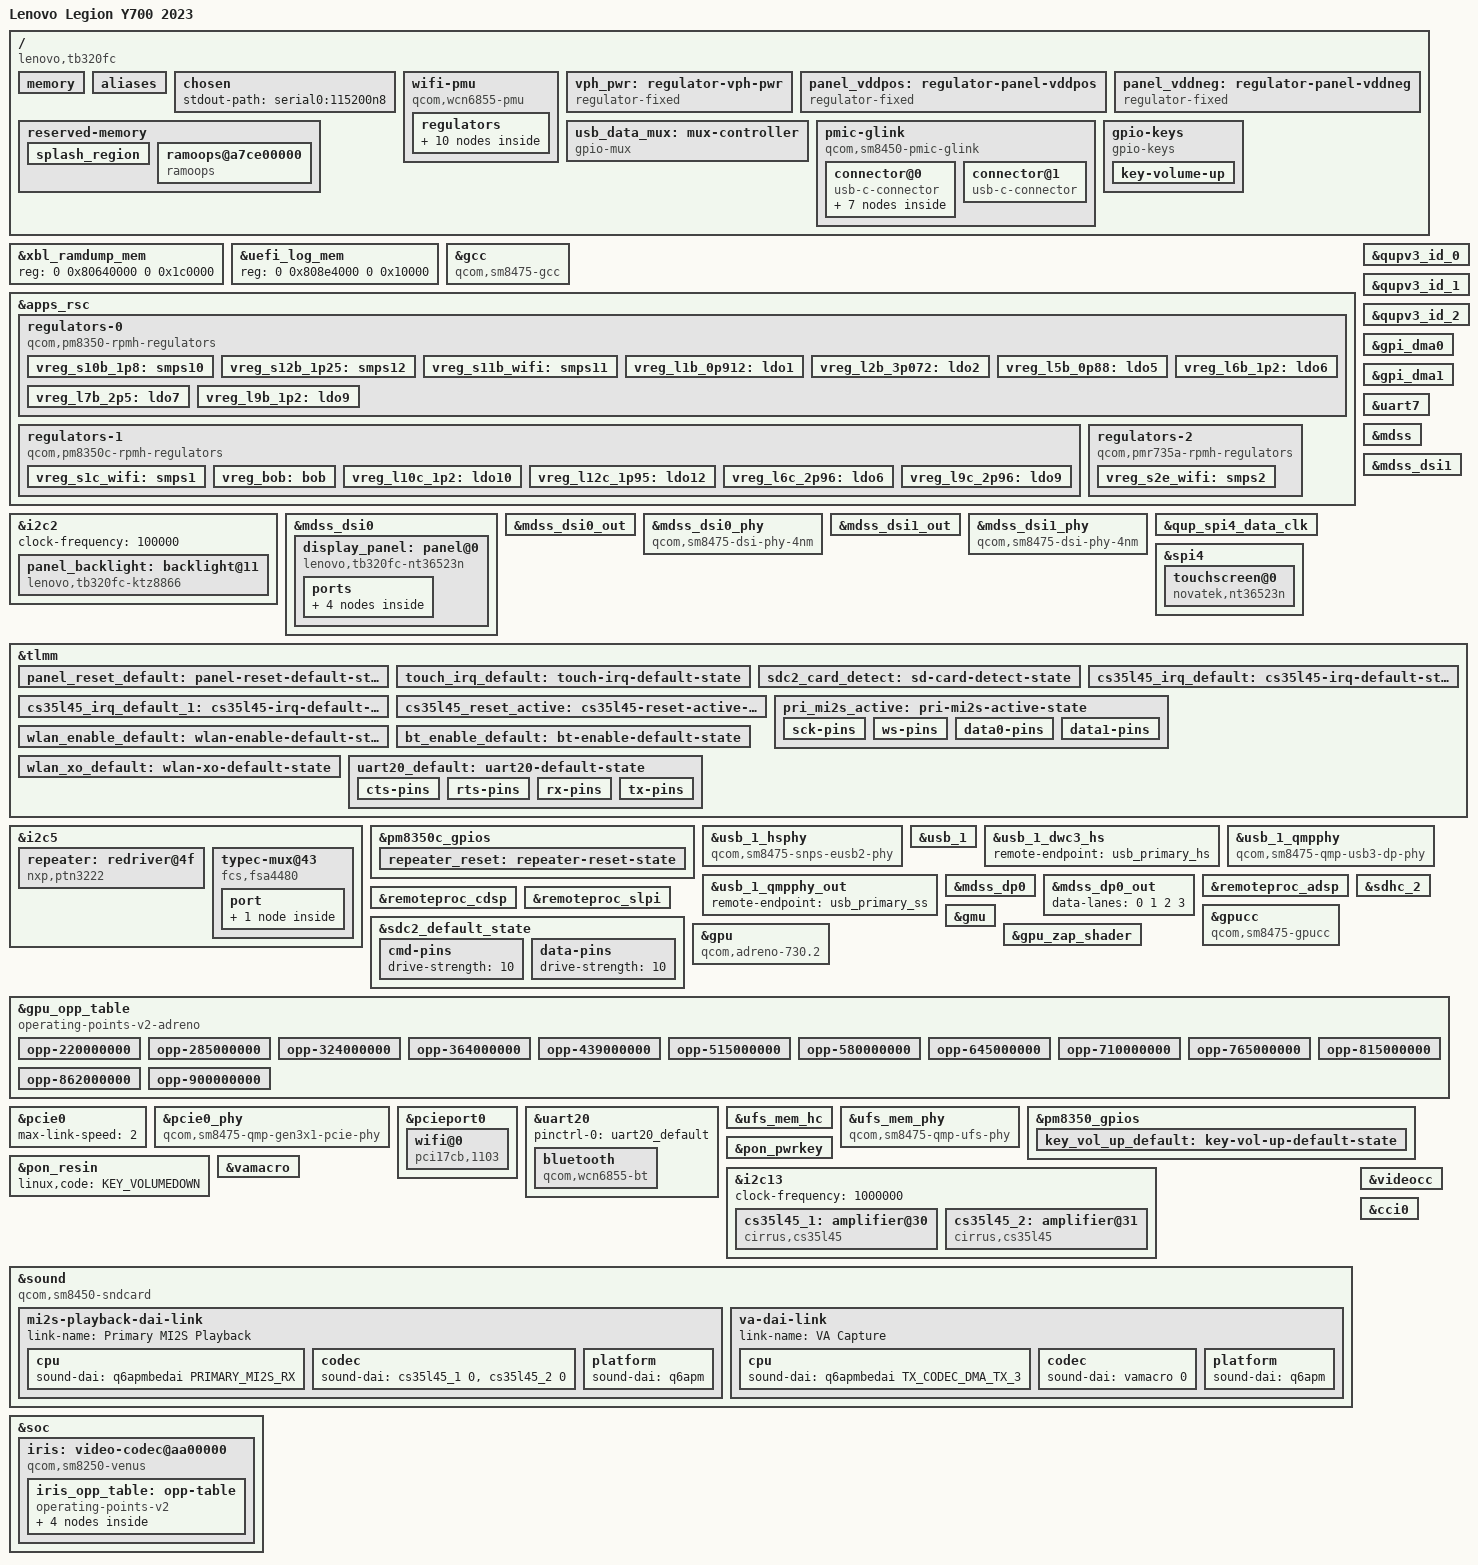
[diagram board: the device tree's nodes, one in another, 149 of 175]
// SPDX-License-Identifier: BSD-3-Clause

/dts-v1/;
#include <dt-bindings/regulator/qcom,rpmh-regulator.h>
#include <dt-bindings/pinctrl/qcom,pmic-gpio.h>
#include <dt-bindings/phy/phy.h>
#include <dt-bindings/input/input.h>
#include <dt-bindings/input/linux-event-codes.h>
#include "sm8450.dtsi"
#include "pm8350.dtsi"
#include "pm8350c.dtsi"
#include "pmk8350.dtsi"

/delete-node/ &xbl_sc_mem;
/delete-node/ &rmtfs_mem;
/delete-node/ &oem_vm_mem;

/ {
	model = "Lenovo Legion Y700 2023";
	compatible = "lenovo,tb320fc", "qcom,sm8475", "qcom,sm8450",
		     "qcom,cape-mtp", "qcom,cape", "qcom,mtp";
	chassis-type = "tablet";
	/* TODO: Remove downstream *-id */
	qcom,msm-id = <0x213 0x10000>;
	qcom,board-id = <0x10008 0>;
	/* TODO: merge this flag during vendor_boot building */
	/* region_country is mandatory as bootloader accept either ROW or PRC */
	region_country = "ROW";

	/delete-node/ memory@a0000000;
	memory {
		device_type = "memory";
		reg = <0 0x80000000 0 0x6a000000>,
		      <0 0xed900000 0 0x12700000>,
		      <8 0x00000000 0 0x39900000>,
		      <9 0x00000000 1 0x80000000>,
		      <8 0x40000000 0 0xc0000000>;
	};

	aliases {
		serial0 = &uart7;
		serial1 = &uart20;
		i2c5 = &i2c5;
		mmc0 = &sdhc_2;
	};
	chosen {
		stdout-path = "serial0:115200n8";
	};

	wifi-pmu {
		compatible = "qcom,wcn6855-pmu";
		pinctrl-names = "default";
		pinctrl-0 = <&wlan_enable_default &bt_enable_default &wlan_xo_default>;
		wlan-enable-gpios = <&tlmm 80 GPIO_ACTIVE_HIGH>;
		bt-enable-gpios = <&tlmm 81 GPIO_ACTIVE_HIGH>;
		swctrl-gpios = <&tlmm 82 GPIO_ACTIVE_HIGH>;
		xo-clk-gpios = <&tlmm 204 GPIO_ACTIVE_HIGH>;
		vddio-supply = <&vreg_s10b_1p8>;
		vddaon-supply = <&vreg_s11b_wifi>;
		vddpmu-supply = <&vreg_s12b_1p25>;
		vddpmumx-supply = <&vreg_s2e_wifi>;
		vddpmucx-supply = <&vreg_s11b_wifi>;
		vddrfa0p95-supply = <&vreg_s11b_wifi>;
		vddrfa1p3-supply = <&vreg_s12b_1p25>;
		vddrfa1p9-supply = <&vreg_s1c_wifi>;
		vddpcie1p3-supply = <&vreg_s12b_1p25>;
		vddpcie1p9-supply = <&vreg_s1c_wifi>;

		regulators {
			vreg_pmu_rfa_cmn_0p8: ldo0 {
				regulator-name = "vreg_pmu_rfa_cmn_0p8";
			};

			vreg_pmu_aon_0p8: ldo1 {
				regulator-name = "vreg_pmu_aon_0p8";
			};

			vreg_pmu_wlcx_0p8: ldo2 {
				regulator-name = "vreg_pmu_wlcx_0p8";
			};

			vreg_pmu_wlmx_0p8: ldo3 {
				regulator-name = "vreg_pmu_wlmx_0p8";
			};

			vreg_pmu_btcmx_0p8: ldo4 {
				regulator-name = "vreg_pmu_btcmx_0p8";
			};

			vreg_pmu_pcie_1p8: ldo5 {
				regulator-name = "vreg_pmu_pcie_1p8";
			};

			vreg_pmu_pcie_0p9: ldo6 {
				regulator-name = "vreg_pmu_pcie_0p9";
			};

			vreg_pmu_rfa_0p8: ldo7 {
				regulator-name = "vreg_pmu_rfa_0p8";
			};

			vreg_pmu_rfa_1p2: ldo8 {
				regulator-name = "vreg_pmu_rfa_1p2";
			};

			vreg_pmu_rfa_1p7: ldo9 {
				regulator-name = "vreg_pmu_rfa_1p7";
			};
		};
	};

	vph_pwr: regulator-vph-pwr {
		compatible = "regulator-fixed";
		regulator-name = "vph_pwr";
		regulator-min-microvolt = <3700000>;
		regulator-max-microvolt = <3700000>;
		regulator-always-on;
	};

	panel_vddpos: regulator-panel-vddpos {
		compatible = "regulator-fixed";
		regulator-name = "panel_vddpos";
		regulator-min-microvolt = <5500000>;
		regulator-max-microvolt = <5500000>;
		gpio = <&tlmm 61 GPIO_ACTIVE_HIGH>;
		enable-active-high;
		regulator-boot-on;
		startup-delay-us = <10000>;
	};

	panel_vddneg: regulator-panel-vddneg {
		compatible = "regulator-fixed";
		regulator-name = "panel_vddneg";
		regulator-min-microvolt = <5500000>;
		regulator-max-microvolt = <5500000>;
		vin-supply = <&panel_vddpos>;
		gpio = <&tlmm 65 GPIO_ACTIVE_HIGH>;
		enable-active-high;
		regulator-boot-on;
		startup-delay-us = <10000>;
	};

	reserved-memory {
		splash_region: splash_region {
			reg = <0 0xb8000000 0 0x2b00000>;
			no-map;
		};
		ramoops@a7ce00000 {
			compatible = "ramoops";
			reg = <0xa 0x7ce00000 0 0x200000>;
			pmsg-size = <0x200000>;
			mem-type = <2>;
		};
	};
};

&xbl_ramdump_mem { reg = <0 0x80640000 0 0x1c0000>; };
&uefi_log_mem { reg = <0 0x808e4000 0 0x10000>; };
&gcc { compatible = "qcom,sm8475-gcc"; };

&apps_rsc {
	regulators-0 {
		compatible = "qcom,pm8350-rpmh-regulators";
		qcom,pmic-id = "b";
		vdd-l1-l4-supply = <&vreg_s11b_wifi>;
		vdd-s10-supply = <&vph_pwr>;
		vdd-s11-supply = <&vph_pwr>;
		vdd-s12-supply = <&vph_pwr>;
		vdd-l2-l7-supply = <&vreg_bob>;
		vdd-l3-l5-supply = <&vreg_bob>;
		vdd-l6-l9-l10-supply = <&vreg_s12b_1p25>;
		vreg_s10b_1p8: smps10 {
			regulator-name = "vreg_s10b_1p8";
			regulator-min-microvolt = <1800000>;
			regulator-max-microvolt = <1800000>;
		};
		vreg_s12b_1p25: smps12 {
			regulator-name = "vreg_s12b_1p25";
			regulator-min-microvolt = <1224000>;
			regulator-max-microvolt = <1400000>;
		};
		vreg_s11b_wifi: smps11 {
			regulator-name = "vreg_s11b_wifi";
			regulator-min-microvolt = <966000>;
			regulator-max-microvolt = <1170000>;
		};
		vreg_l1b_0p912: ldo1 {
			regulator-name = "vreg_l1b_0p912";
			regulator-min-microvolt = <912000>;
			regulator-max-microvolt = <912000>;
			regulator-initial-mode = <RPMH_REGULATOR_MODE_HPM>;
		};
		vreg_l2b_3p072: ldo2 {
			regulator-name = "vreg_l2b_3p072";
			regulator-min-microvolt = <3072000>;
			regulator-max-microvolt = <3072000>;
			regulator-initial-mode = <RPMH_REGULATOR_MODE_HPM>;
		};
		vreg_l5b_0p88: ldo5 {
			regulator-name = "vreg_l5b_0p88";
			regulator-min-microvolt = <880000>;
			regulator-max-microvolt = <880000>;
			regulator-initial-mode = <RPMH_REGULATOR_MODE_HPM>;
		};
		vreg_l6b_1p2: ldo6 {
			regulator-name = "vreg_l6b_1p2";
			regulator-min-microvolt = <1200000>;
			regulator-max-microvolt = <1200000>;
			regulator-initial-mode = <RPMH_REGULATOR_MODE_HPM>;
		};
		vreg_l7b_2p5: ldo7 {
			regulator-name = "vreg_l7b_2p5";
			regulator-min-microvolt = <2504000>;
			regulator-max-microvolt = <2504000>;
			regulator-initial-mode = <RPMH_REGULATOR_MODE_HPM>;
		};
		vreg_l9b_1p2: ldo9 {
			regulator-name = "vreg_l9b_1p2";
			regulator-min-microvolt = <1200000>;
			regulator-max-microvolt = <1200000>;
			regulator-initial-mode = <RPMH_REGULATOR_MODE_HPM>;
		};
	};
	regulators-1 {
		compatible = "qcom,pm8350c-rpmh-regulators";
		qcom,pmic-id = "c";
		vdd-bob-supply = <&vph_pwr>;
		vdd-s1-supply = <&vph_pwr>;
		vdd-l6-l9-l11-supply = <&vreg_bob>;
		vdd-l10-supply = <&vreg_s12b_1p25>;
		vdd-l1-l12-supply = <&vreg_bob>;
		vreg_s1c_wifi: smps1 {
			regulator-name = "vreg_s1c_wifi";
			regulator-min-microvolt = <1900000>;
			regulator-max-microvolt = <2024000>;
		};
		vreg_bob: bob {
			regulator-name = "vreg_bob";
			regulator-min-microvolt = <3008000>;
			regulator-max-microvolt = <3960000>;
			regulator-initial-mode = <RPMH_REGULATOR_MODE_AUTO>;
		};
		vreg_l10c_1p2: ldo10 {
			regulator-name = "vreg_l10c_1p2";
			regulator-min-microvolt = <1200000>;
			regulator-max-microvolt = <1200000>;
			regulator-initial-mode = <RPMH_REGULATOR_MODE_HPM>;
		};
		vreg_l12c_1p95: ldo12 {
			regulator-name = "vreg_l12c_1p95";
			regulator-min-microvolt = <1950000>;
			regulator-max-microvolt = <1980000>;
			regulator-initial-mode = <RPMH_REGULATOR_MODE_HPM>;
			regulator-boot-on;
		};
		vreg_l6c_2p96: ldo6 {
			regulator-name = "vreg_l6c_2p96";
			regulator-min-microvolt = <2960000>;
			regulator-max-microvolt = <2960000>;
			regulator-initial-mode = <RPMH_REGULATOR_MODE_HPM>;
		};
		vreg_l9c_2p96: ldo9 {
			regulator-name = "vreg_l9c_2p96";
			regulator-min-microvolt = <2960000>;
			regulator-max-microvolt = <2960000>;
			regulator-initial-mode = <RPMH_REGULATOR_MODE_HPM>;
		};
	};
	regulators-2 {
		compatible = "qcom,pmr735a-rpmh-regulators";
		qcom,pmic-id = "e";
		vdd-s2-supply = <&vph_pwr>;
		vreg_s2e_wifi: smps2 {
			regulator-name = "vreg_s2e_wifi";
			regulator-min-microvolt = <1012000>;
			regulator-max-microvolt = <1040000>;
		};
	};
};

&qupv3_id_0 { status = "okay"; };
&qupv3_id_1 { status = "okay"; };
&qupv3_id_2 { status = "okay"; };
&gpi_dma0 { status = "okay"; };
&gpi_dma1 { status = "okay"; };
&uart7 { status = "okay"; };

&i2c2 {
	clock-frequency = <100000>;
	status = "okay";

	panel_backlight: backlight@11 {
		compatible = "lenovo,tb320fc-ktz8866", "kinetic,ktz8866";
		reg = <0x11>;
		vddpos-supply = <&panel_vddpos>;
		vddneg-supply = <&panel_vddneg>;
		enable-gpios = <&tlmm 62 GPIO_ACTIVE_HIGH>;
		current-num-sinks = <4>;
		default-brightness = <1027>;
		kinetic,current-ramp-delay-ms = <256>;
		kinetic,enable-lcd-bias;
	};
};

&mdss {
	status = "okay";
};

&mdss_dsi0 {
	vdda-supply = <&vreg_l10c_1p2>;
	qcom,dual-dsi-mode;
	qcom,sync-dual-dsi;
	qcom,master-dsi;
	status = "okay";

	display_panel: panel@0 {
		compatible = "lenovo,tb320fc-nt36523n";
		reg = <0>;
		vddio-supply = <&vreg_l12c_1p95>;
		vddpos-supply = <&panel_vddpos>;
		vddneg-supply = <&panel_vddneg>;
		reset-gpios = <&tlmm 0 GPIO_ACTIVE_LOW>;
		pinctrl-names = "default";
		pinctrl-0 = <&panel_reset_default>;
		backlight = <&panel_backlight>;

		ports {
			#address-cells = <1>;
			#size-cells = <0>;

			port@0 {
				reg = <0>;

				panel_in_0: endpoint {
					remote-endpoint = <&mdss_dsi0_out>;
				};
			};

			port@1 {
				reg = <1>;

				panel_in_1: endpoint {
					remote-endpoint = <&mdss_dsi1_out>;
				};
			};
		};
	};
};

&mdss_dsi0_out {
	data-lanes = <0 1 2>;
	remote-endpoint = <&panel_in_0>;
};

&mdss_dsi0_phy {
	compatible = "qcom,sm8475-dsi-phy-4nm";
	vdds-supply = <&vreg_l5b_0p88>;
	phy-type = <PHY_TYPE_CPHY>;
	status = "okay";
};

&mdss_dsi1 {
	vdda-supply = <&vreg_l10c_1p2>;
	qcom,dual-dsi-mode;
	qcom,sync-dual-dsi;
	assigned-clock-parents = <&mdss_dsi0_phy DSI_BYTE_PLL_CLK>,
				 <&mdss_dsi0_phy DSI_PIXEL_PLL_CLK>;
	status = "okay";
};

&mdss_dsi1_out {
	data-lanes = <0 1 2>;
	remote-endpoint = <&panel_in_1>;
};

&mdss_dsi1_phy {
	compatible = "qcom,sm8475-dsi-phy-4nm";
	vdds-supply = <&vreg_l5b_0p88>;
	phy-type = <PHY_TYPE_CPHY>;
	status = "okay";
};

&qup_spi4_data_clk {
	drive-strength = <6>;
	bias-disable;
};

&spi4 {
	status = "okay";

	touchscreen@0 {
		compatible = "novatek,nt36523n";
		reg = <0>;
		spi-max-frequency = <9600000>;
		interrupts-extended = <&tlmm 21 IRQ_TYPE_EDGE_RISING>;
		pinctrl-names = "default";
		pinctrl-0 = <&touch_irq_default>;
		panel = <&display_panel>;
		firmware-name = "novatek/novatek_ts_fw.bin";
		touchscreen-size-x = <1600>;
		touchscreen-size-y = <2560>;
		novatek,pen-support;
	};
};

&tlmm {
	panel_reset_default: panel-reset-default-state {
		pins = "gpio0";
		function = "gpio";
		drive-strength = <8>;
		bias-disable;
	};

	touch_irq_default: touch-irq-default-state {
		pins = "gpio21";
		function = "gpio";
		drive-strength = <8>;
		bias-pull-up;
		input-enable;
	};
};

&i2c5 {
	status = "okay";
	repeater: redriver@4f {
		compatible = "nxp,ptn3222";
		reg = <0x4f>;
		#phy-cells = <0>;
		vdd1v8-supply = <&vreg_s10b_1p8>;
		vdd3v3-supply = <&vreg_l2b_3p072>;
		reset-gpios = <&pm8350c_gpios 7 GPIO_ACTIVE_LOW>;
		pinctrl-names = "default";
		pinctrl-0 = <&repeater_reset>;
	};
};

&pm8350c_gpios {
	repeater_reset: repeater-reset-state {
		pins = "gpio7";
		function = "normal";
		power-source = <1>;
		bias-disable;
		output-high;
	};
};

&usb_1_hsphy {
	compatible = "qcom,sm8475-snps-eusb2-phy", "qcom,sm8550-snps-eusb2-phy";
	reg = <0 0x088e3000 0 0x154>;
	vdd-supply = <&vreg_l5b_0p88>;
	vdda12-supply = <&vreg_l10c_1p2>;
	phys = <&repeater>;
	status = "okay";
};

&usb_1 {
	status = "okay";
	dr_mode = "otg";
	role-switch-default-mode = "peripheral";
	maximum-speed = "high-speed";
	qcom,select-utmi-as-pipe-clk;
	phys = <&usb_1_hsphy>;
	phy-names = "usb2-phy";
	usb-role-switch;
	mux-states = <&usb_data_mux 0>, <&usb_data_mux 1>;
	mux-state-names = "usb-device", "usb-host";
	mux-settle-time-us = <50000>;
};

/ {
	usb_data_mux: mux-controller {
		compatible = "gpio-mux";
		#mux-state-cells = <1>;
		mux-gpios = <&tlmm 88 GPIO_ACTIVE_HIGH>;
		idle-state = <0>;
	};

	pmic-glink {
		compatible = "qcom,sm8450-pmic-glink", "qcom,pmic-glink";
		#address-cells = <1>;
		#size-cells = <0>;

		connector@0 {
			compatible = "usb-c-connector";
			reg = <0>;
			power-role = "dual";
			data-role = "dual";
			ports {
				#address-cells = <1>;
				#size-cells = <0>;
				port@0 {
					reg = <0>;
					usb_primary_hs: endpoint {
						remote-endpoint = <&usb_1_dwc3_hs>;
					};
				};
				port@1 {
					reg = <1>;
					usb_primary_ss: endpoint {
						remote-endpoint = <&usb_1_qmpphy_out>;
					};
				};
				port@2 {
					reg = <2>;
					usb_primary_sbu: endpoint {
						remote-endpoint = <&fsa4480_primary_sbu>;
					};
				};
			};
		};

		connector@1 {
			compatible = "usb-c-connector";
			reg = <1>;
			power-role = "dual";
			data-role = "dual";
		};
	};

	gpio-keys {
		compatible = "gpio-keys";
		label = "gpio-keys";

		pinctrl-names = "default";
		pinctrl-0 = <&key_vol_up_default>;

		key-volume-up {
			label = "volume_up";
			gpios = <&pm8350_gpios 6 GPIO_ACTIVE_LOW>;
			linux,input-type = <1>;
			linux,code = <KEY_VOLUMEUP>;
			gpio-key,wakeup;
			debounce-interval = <15>;
		};
	};
};

&usb_1_dwc3_hs {
	remote-endpoint = <&usb_primary_hs>;
};

&usb_1_qmpphy {
	compatible = "qcom,sm8475-qmp-usb3-dp-phy";
	vdda-phy-supply = <&vreg_l1b_0p912>;
	vdda-pll-supply = <&vreg_l10c_1p2>;
	status = "okay";
};

&usb_1_qmpphy_out {
	remote-endpoint = <&usb_primary_ss>;
};

&i2c5 {
	typec-mux@43 {
		compatible = "fcs,fsa4480";
		reg = <0x43>;
		mode-switch;
		orientation-switch;
		port {
			fsa4480_primary_sbu: endpoint {
				remote-endpoint = <&usb_primary_sbu>;
			};
		};
	};
};

&mdss_dp0 {
	status = "okay";
};

&mdss_dp0_out {
	data-lanes = <0 1 2 3>;
};

&remoteproc_adsp {
	firmware-name = "qcom/lenovo/tb320fc/adsp/adsp.mdt";
	status = "okay";
};

&remoteproc_cdsp {
	firmware-name = "qcom/lenovo/tb320fc/cdsp/cdsp.mdt";
	status = "okay";
};

&remoteproc_slpi {
	firmware-name = "qcom/lenovo/tb320fc/slpi/slpi.mdt";
	status = "okay";
};

&sdhc_2 {
	cd-gpios = <&tlmm 92 GPIO_ACTIVE_HIGH>;
	pinctrl-names = "default", "sleep";
	pinctrl-0 = <&sdc2_default_state &sdc2_card_detect>;
	pinctrl-1 = <&sdc2_sleep_state &sdc2_card_detect>;
	vmmc-supply = <&vreg_l9c_2p96>;
	vqmmc-supply = <&vreg_l6c_2p96>;
	max-frequency = <50000000>;
	no-1-8-v;
	no-sdio;
	no-mmc;
	status = "okay";
};

&sdc2_default_state {
	cmd-pins {
		drive-strength = <10>;
	};
	data-pins {
		drive-strength = <10>;
	};
};

&tlmm {
	sdc2_card_detect: sd-card-detect-state {
		pins = "gpio92";
		function = "gpio";
		drive-strength = <2>;
		bias-pull-up;
		input-enable;
	};

	cs35l45_irq_default: cs35l45-irq-default-state {
		pins = "gpio172";
		function = "gpio";
		bias-pull-up;
		input-enable;
		drive-strength = <2>;
	};

	cs35l45_irq_default_1: cs35l45-irq-default-1-state {
		pins = "gpio1";
		function = "gpio";
		bias-pull-up;
		input-enable;
		drive-strength = <2>;
	};

	cs35l45_reset_active: cs35l45-reset-active-state {
		pins = "gpio123";
		function = "gpio";
		drive-strength = <16>;
		output-high;
	};

	pri_mi2s_active: pri-mi2s-active-state {
		sck-pins {
			pins = "gpio126";
			function = "mi2s0_sck";
			drive-strength = <8>;
			bias-disable;
			output-high;
		};

		ws-pins {
			pins = "gpio129";
			function = "mi2s0_ws";
			drive-strength = <8>;
			bias-disable;
			output-high;
		};

		data0-pins {
			pins = "gpio127";
			function = "mi2s0_data0";
			drive-strength = <8>;
			bias-disable;
			output-high;
		};

		data1-pins {
			pins = "gpio128";
			function = "mi2s0_data1";
			drive-strength = <8>;
			bias-disable;
			output-high;
		};
	};
};

&gpucc { compatible = "qcom,sm8475-gpucc"; };
&gpu {
	compatible = "qcom,adreno-730.2", "qcom,adreno";
	interconnects = <&gem_noc MASTER_GFX3D 0 &mc_virt SLAVE_EBI1 0>;
	interconnect-names = "gfx-mem";
	status = "okay";
};
&gmu { status = "okay"; };
&gpu_zap_shader { firmware-name = "qcom/lenovo/tb320fc/a730_zap.mdt"; };
&gpu_opp_table {
	compatible = "operating-points-v2-adreno", "operating-points-v2";
	/delete-node/ opp-818000000;
	/delete-node/ opp-791000000;
	/delete-node/ opp-734000000;
	/delete-node/ opp-640000000;
	/delete-node/ opp-599000000;
	/delete-node/ opp-545000000;
	/delete-node/ opp-492000000;
	/delete-node/ opp-421000000;
	/delete-node/ opp-350000000;
	/delete-node/ opp-317000000;
	/delete-node/ opp-285000000;
	/delete-node/ opp-220000000;
	/delete-node/ opp-324000000;

	opp-220000000 {
		opp-hz = /bits/ 64 <220000000>;
		opp-level = <RPMH_REGULATOR_LEVEL_MIN_SVS>;
		qcom,opp-cx-level = <RPMH_REGULATOR_LEVEL_LOW_SVS>;
		opp-peak-kBps = <1761718>;
	};
	opp-285000000 {
		opp-hz = /bits/ 64 <285000000>;
		opp-level = <RPMH_REGULATOR_LEVEL_LOW_SVS_D1>;
		qcom,opp-cx-level = <RPMH_REGULATOR_LEVEL_LOW_SVS>;
		opp-peak-kBps = <1761718>;
	};
	opp-324000000 {
		opp-hz = /bits/ 64 <324000000>;
		opp-level = <RPMH_REGULATOR_LEVEL_LOW_SVS>;
		qcom,opp-cx-level = <RPMH_REGULATOR_LEVEL_LOW_SVS>;
		opp-peak-kBps = <1761718>;
	};
	opp-364000000 {
		opp-hz = /bits/ 64 <364000000>;
		opp-level = <RPMH_REGULATOR_LEVEL_LOW_SVS_L1>;
		qcom,opp-cx-level = <RPMH_REGULATOR_LEVEL_SVS>;
		opp-peak-kBps = <2136718>;
	};
	opp-439000000 {
		opp-hz = /bits/ 64 <439000000>;
		opp-level = <RPMH_REGULATOR_LEVEL_LOW_SVS_L2>;
		qcom,opp-cx-level = <RPMH_REGULATOR_LEVEL_SVS>;
		opp-peak-kBps = <6074218>;
	};
	opp-515000000 {
		opp-hz = /bits/ 64 <515000000>;
		opp-level = <RPMH_REGULATOR_LEVEL_SVS>;
		qcom,opp-cx-level = <RPMH_REGULATOR_LEVEL_SVS>;
		opp-peak-kBps = <6074218>;
	};
	opp-580000000 {
		opp-hz = /bits/ 64 <580000000>;
		opp-level = <RPMH_REGULATOR_LEVEL_SVS_L0>;
		qcom,opp-cx-level = <RPMH_REGULATOR_LEVEL_SVS_L1>;
		opp-peak-kBps = <8171875>;
	};
	opp-645000000 {
		opp-hz = /bits/ 64 <645000000>;
		opp-level = <RPMH_REGULATOR_LEVEL_SVS_L1>;
		qcom,opp-cx-level = <RPMH_REGULATOR_LEVEL_SVS_L1>;
		opp-peak-kBps = <8171875>;
	};
	opp-710000000 {
		opp-hz = /bits/ 64 <710000000>;
		opp-level = <RPMH_REGULATOR_LEVEL_SVS_L2>;
		qcom,opp-cx-level = <RPMH_REGULATOR_LEVEL_NOM>;
		opp-peak-kBps = <12484375>;
	};
	opp-765000000 {
		opp-hz = /bits/ 64 <765000000>;
		opp-level = <RPMH_REGULATOR_LEVEL_NOM>;
		qcom,opp-cx-level = <RPMH_REGULATOR_LEVEL_NOM>;
		opp-peak-kBps = <12484375>;
	};
	opp-815000000 {
		opp-hz = /bits/ 64 <815000000>;
		opp-level = <RPMH_REGULATOR_LEVEL_NOM_L1>;
		qcom,opp-cx-level = <RPMH_REGULATOR_LEVEL_NOM_L1>;
		opp-peak-kBps = <13085937>;
	};
	opp-862000000 {
		opp-hz = /bits/ 64 <862000000>;
		opp-level = <RPMH_REGULATOR_LEVEL_TURBO>;
		qcom,opp-cx-level = <RPMH_REGULATOR_LEVEL_TURBO>;
		opp-peak-kBps = <13085937>;
	};
	opp-900000000 {
		opp-hz = /bits/ 64 <900000000>;
		opp-level = <RPMH_REGULATOR_LEVEL_TURBO_L1>;
		qcom,opp-cx-level = <RPMH_REGULATOR_LEVEL_TURBO_L1>;
		opp-peak-kBps = <13085937>;
	};
};

&pcie0 {
	max-link-speed = <2>;
	status = "okay";
};

&pcie0_phy {
	compatible = "qcom,sm8475-qmp-gen3x1-pcie-phy";
	vdda-phy-supply = <&vreg_l5b_0p88>;
	vdda-pll-supply = <&vreg_l10c_1p2>;
	status = "okay";
};

&pcieport0 {
	wifi@0 {
		compatible = "pci17cb,1103";
		reg = <0x10000 0 0 0 0>;

		vddrfacmn-supply = <&vreg_pmu_rfa_cmn_0p8>;
		vddaon-supply = <&vreg_pmu_aon_0p8>;
		vddwlcx-supply = <&vreg_pmu_wlcx_0p8>;
		vddwlmx-supply = <&vreg_pmu_wlmx_0p8>;
		vddpcie1p8-supply = <&vreg_pmu_pcie_1p8>;
		vddpcie0p9-supply = <&vreg_pmu_pcie_0p9>;
		vddrfa0p8-supply = <&vreg_pmu_rfa_0p8>;
		vddrfa1p2-supply = <&vreg_pmu_rfa_1p2>;
		vddrfa1p8-supply = <&vreg_pmu_rfa_1p7>;
	};
};

&tlmm {
	wlan_enable_default: wlan-enable-default-state {
		pins = "gpio80";
		function = "gpio";
		drive-strength = <16>;
		bias-pull-down;
		output-low;
	};
	bt_enable_default: bt-enable-default-state {
		pins = "gpio81";
		function = "gpio";
		drive-strength = <16>;
		bias-pull-down;
		output-low;
	};
	wlan_xo_default: wlan-xo-default-state {
		pins = "gpio204";
		function = "gpio";
		drive-strength = <16>;
		bias-pull-down;
		output-low;
	};

	uart20_default: uart20-default-state {
		cts-pins {
			pins = "gpio76";
			function = "qup20";
			bias-disable;
		};

		rts-pins {
			pins = "gpio77";
			function = "qup20";
			bias-disable;
		};

		rx-pins {
			pins = "gpio78";
			function = "qup20";
			bias-disable;
		};

		tx-pins {
			pins = "gpio79";
			function = "qup20";
			bias-disable;
		};
	};
};

&uart20 {
	pinctrl-0 = <&uart20_default>;
	pinctrl-names = "default";
	status = "okay";

	bluetooth {
		compatible = "qcom,wcn6855-bt";

		vddrfacmn-supply = <&vreg_pmu_rfa_cmn_0p8>;
		vddaon-supply = <&vreg_pmu_aon_0p8>;
		vddwlcx-supply = <&vreg_pmu_wlcx_0p8>;
		vddwlmx-supply = <&vreg_pmu_wlmx_0p8>;
		vddbtcmx-supply = <&vreg_pmu_btcmx_0p8>;
		vddrfa0p8-supply = <&vreg_pmu_rfa_0p8>;
		vddrfa1p2-supply = <&vreg_pmu_rfa_1p2>;
		vddrfa1p7-supply = <&vreg_pmu_rfa_1p7>;
		max-speed = <3200000>;
	};
};

&ufs_mem_hc {
	reset-gpios = <&tlmm 210 GPIO_ACTIVE_LOW>;
	vcc-supply = <&vreg_l7b_2p5>;
	vcc-max-microamp = <1100000>;
	vccq-supply = <&vreg_l9b_1p2>;
	vccq-max-microamp = <1200000>;
	vdd-hba-supply = <&vreg_l9b_1p2>;
	status = "okay";
};

&ufs_mem_phy {
	compatible = "qcom,sm8475-qmp-ufs-phy";
	reg = <0 0x01d80000 0 0x2000>;
	vdda-phy-supply = <&vreg_l5b_0p88>;
	vdda-pll-supply = <&vreg_l6b_1p2>;
	status = "okay";
};

&pm8350_gpios {
	key_vol_up_default: key-vol-up-default-state {
		pins = "gpio6";
		function = "normal";
		input-enable;
		bias-pull-up;
		power-source = <1>;
	};
};

&pon_pwrkey {
	status = "okay";
};

&pon_resin {
	linux,code = <KEY_VOLUMEDOWN>;
	status = "okay";
};

&i2c13 {
	clock-frequency = <1000000>;
	status = "okay";

	cs35l45_1: amplifier@30 {
		compatible = "cirrus,cs35l45";
		reg = <0x30>;
		interrupt-parent = <&tlmm>;
		interrupts = <172 IRQ_TYPE_LEVEL_LOW>;
		vdd-a-supply = <&vreg_s10b_1p8>;
		vdd-batt-supply = <&vreg_bob>;
		pinctrl-names = "default";
		pinctrl-0 = <&cs35l45_irq_default &cs35l45_reset_active>;
		cirrus,asp-sdout-hiz-ctrl = <3>;
		#sound-dai-cells = <1>;
		sound-name-prefix = "SPK1";
	};

	cs35l45_2: amplifier@31 {
		compatible = "cirrus,cs35l45";
		reg = <0x31>;
		interrupt-parent = <&tlmm>;
		interrupts = <1 IRQ_TYPE_LEVEL_LOW>;
		vdd-a-supply = <&vreg_s10b_1p8>;
		vdd-batt-supply = <&vreg_bob>;
		pinctrl-names = "default";
		pinctrl-0 = <&cs35l45_irq_default_1 &cs35l45_reset_active>;
		cirrus,asp-sdout-hiz-ctrl = <3>;
		#sound-dai-cells = <1>;
		sound-name-prefix = "SPK2";
	};
};

&vamacro {
	pinctrl-0 = <&dmic01_default>, <&dmic23_default>;
	pinctrl-names = "default";
	vdd-micb-supply = <&vreg_s10b_1p8>;
	qcom,dmic-sample-rate = <600000>;
	status = "okay";
};

&sound {
	compatible = "qcom,sm8450-sndcard";
	model = "Lenovo-TB320FC";
	pinctrl-0 = <&pri_mi2s_active>;
	pinctrl-names = "default";

	mi2s-playback-dai-link {
		link-name = "Primary MI2S Playback";

		cpu {
			sound-dai = <&q6apmbedai PRIMARY_MI2S_RX>;
		};

		codec {
			sound-dai = <&cs35l45_1 0>, <&cs35l45_2 0>;
		};

		platform {
			sound-dai = <&q6apm>;
		};
	};

	va-dai-link {
		link-name = "VA Capture";

		cpu {
			sound-dai = <&q6apmbedai TX_CODEC_DMA_TX_3>;
		};

		codec {
			sound-dai = <&vamacro 0>;
		};

		platform {
			sound-dai = <&q6apm>;
		};
	};
};

&videocc {
	status = "okay";
};

&cci0 {
	status = "okay";
};

&soc {
	iris: video-codec@aa00000 {
		compatible = "qcom,sm8250-venus";
		reg = <0 0x0aa00000 0 0xf0000>;
		interrupts = <GIC_SPI 174 IRQ_TYPE_LEVEL_HIGH>;

		clocks = <&gcc GCC_VIDEO_AXI0_CLK>,
			 <&videocc VIDEO_CC_MVS0C_CLK>,
			 <&videocc VIDEO_CC_MVS0_CLK>;
		clock-names = "iface",
			      "core",
			      "vcodec0_core";

		power-domains = <&videocc VIDEO_CC_MVS0C_GDSC>,
				<&videocc VIDEO_CC_MVS0_GDSC>,
				<&rpmhpd RPMHPD_MXC>,
				<&rpmhpd RPMHPD_MMCX>;
		power-domain-names = "venus",
				     "vcodec0",
				     "mx",
				     "mmcx";

		resets = <&gcc GCC_VIDEO_AXI0_CLK_ARES>,
			 <&videocc VIDEO_CC_MVS0C_CLK_ARES>;
		reset-names = "bus", "core";

		interconnects = <&gem_noc MASTER_APPSS_PROC QCOM_ICC_TAG_ACTIVE_ONLY
				 &config_noc SLAVE_VENUS_CFG QCOM_ICC_TAG_ACTIVE_ONLY>,
				<&mmss_noc MASTER_VIDEO QCOM_ICC_TAG_ALWAYS
				 &mc_virt SLAVE_EBI1 QCOM_ICC_TAG_ALWAYS>;
		interconnect-names = "cpu-cfg",
				     "video-mem";

		memory-region = <&video_mem>;

		iommus = <&apps_smmu 0x2180 0x0400>;

		operating-points-v2 = <&iris_opp_table>;

		status = "okay";

		iris_opp_table: opp-table {
			compatible = "operating-points-v2";

			opp-240000000 {
				opp-hz = /bits/ 64 <240000000>;
				required-opps = <&rpmhpd_opp_svs>,
						<&rpmhpd_opp_low_svs>;
			};

			opp-338000000 {
				opp-hz = /bits/ 64 <338000000>;
				required-opps = <&rpmhpd_opp_svs>,
						<&rpmhpd_opp_svs>;
			};

			opp-366000000 {
				opp-hz = /bits/ 64 <366000000>;
				required-opps = <&rpmhpd_opp_svs_l1>,
						<&rpmhpd_opp_svs_l1>;
			};

			opp-444000000 {
				opp-hz = /bits/ 64 <444000000>;
				required-opps = <&rpmhpd_opp_svs_l1>,
						<&rpmhpd_opp_nom>;
			};
		};
	};
};

